# M0A21 register map
File version: 1.0
Registers are 32-bit, read-write, reset 0x0 unless marked. A register's access mark holds for its fields unless they carry their own. Offsets are from the block's base; [hi:lo] are bit positions; {n}, {i} and the like mark numbered series.

## FMC — FMC Register Map
Base 0x4000C000
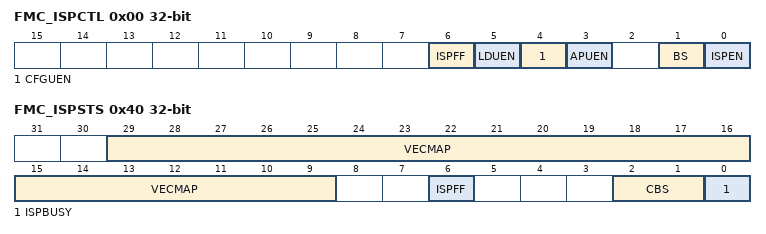
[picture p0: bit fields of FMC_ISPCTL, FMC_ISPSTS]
0x00 FMC_ISPCTL (reset mask 0xFFFFFFF0) — ISP Control Register
  [6] ISPFF — ISP Fail Flag (Write Protect). This bit is set by hardware when a triggered ISP meets any of the following conditions: APROM writes to itself if APUEN is set to 0. LDROM writes to itself if LDUEN is set to 0. CONFIG is erased/programmed if CFGUEN is set to 0. Page Erase command at LOCK mode with ICE connection. Erase or Program command at brown-out detected. Destination address is illegal, such as over an available range. Invalid ISP commands. This bit needs to be cleared by writing 1 to it. Note: This bit is write-protected. Refer to the SYS_REGLCTL register.
  [5] LDUEN — LDROM Update Enable Bit (Write Protect). LDROM update enable bit. Note: This bit is write-protected. Refer to the SYS_REGLCTL register.
    0=LDROM cannot be updated; 1=LDROM can be updated
  [4] CFGUEN — CONFIG Update Enable Bit (Write Protect). Note: This bit is write-protected. Refer to the SYS_REGLCTL register.
    0=CONFIG cannot be updated; 1=CONFIG can be updated
  [3] APUEN — APROM Update Enable Bit (Write Protect). Note: This bit is write-protected. Refer to the SYS_REGLCTL register.
    0=APROM cannot be updated when the chip runs in APROM; 1=APROM can be updated when the chip runs in APROM
  [1] BS — Boot Selection (Write Protect). Set/clear this bit to select next booting from LDROM/APROM, respectively. This bit also functions as chip booting status flag, which can be used to check where chip booted from. This bit is initiated with the inversed value of CBS[1] (CONFIG0[7]) after any reset is happened except CPU reset (RSTS_CPU is 1) or system reset (RSTS_SYS) is happened. Note: This bit is write-protected. Refer to the SYS_REGLCTL register.
    0=Booting from APROM; 1=Booting from LDROM
  [0] ISPEN — ISP Enable Bit (Write Protect). Note: This bit is write-protected. Refer to the SYS_REGLCTL register.
    0=ISP function Disabled; 1=ISP function Enabled
0x04 FMC_ISPADDR — ISP Address Register
  [31:0] ISPADDR — ISP Address. The M0A21/M0A23 is equipped with embedded Flash. ISPADDR[1:0] must be kept 00 for ISP 32-bit operation. For CRC32 Checksum Calculation command, this field is the Flash starting address for checksum calculation, 512 bytes alignment is necessary for checksum calculation. 16/32 Kbytes Flash: ISPADR[8:0] must be kept all 0 for Vector Page Remap Command.
0x08 FMC_ISPDAT — ISP Data Register
  [31:0] ISPDAT — ISP Data. Write data to this register before ISP program operation. Read data from this register after ISP read operation.
0x0C FMC_ISPCMD — ISP Command Register
  [6:0] CMD — ISP CMD. ISP command table is shown below: The other commands are invalid.
    0=Flash 32-bit Read; 4=Read Unique ID; 11=Read Company ID; 13=Read CRC32 Checksum; 33=Flash 32-bit Program; 34=Flash Page Erase; 45=Run CRC32 Checksum Calculation; 46=Vector Remap
0x10 FMC_ISPTRG — ISP Trigger Control Register
  [0] ISPGO — ISP Start Trigger (Write Protect). Write 1 to start ISP operation and this bit will be cleared to 0 by hardware automatically when ISP operation is finished.
    0=ISP operation is finished; 1=ISP is progressed.Note: This bit is write-protected. Refer to the SYS_REGLCTL register
0x14 FMC_DFBA ro reset not defined — Data Flash Base Address
  [31:0] DFBA — Data Flash Base Address. This register indicates Data Flash start address. It is a read only register. The Data Flash is shared with APROM. the content of this register is loaded from CONFIG1.
0x40 FMC_ISPSTS (reset mask 0xF0FFFF0) — ISP Status Register
  [29:9] VECMAP ro — Vector Page Mapping Address (Read Only). All access to 0x0000_0000~0x0000_01FF is remapped to the Flash memory or SRAM address {VECMAP[20:0], 9'h000} ~ {VECMAP[20:0], 9'h1FF}. VECMAP [18:12] should be 0.
  [6] ISPFF — ISP Fail Flag (Write Protect). This bit is the mirror of ISPFF (FMC_ISPCTL[6]), it needs to be cleared by writing 1 to FMC_ISPCTL[6] or FMC_ISPSTS[6]. This bit is set by hardware when a triggered ISP meets any of the following conditions: APROM writes to itself if APUEN is set to 0. LDROM writes to itself if LDUEN is set to 0. CONFIG is erased/programmed if CFGUEN is set to 0. Page Erase command at LOCK mode with ICE connection. Erase or Program command at brown-out detected. Destination address is illegal, such as over an available range. Invalid ISP commands
  [2:1] CBS ro — Boot Selection of CONFIG (Read Only). This bit is initiated with the CBS (CONFIG0[7:6]) after any reset is happened except CPU reset (RSTS_CPU is 1) or system reset (RSTS_SYS) is happened.
    0=LDROM with IAP mode; 1=LDROM without IAP mode; 2=APROM with IAP mode; 3=APROM without IAP mode
  [0] ISPBUSY ro — ISP BUSY (Read Only)
    0=ISP operation is finished; 1=ISP operation is busy
